# System_Clock_5 register map
Vendor: Texas Instruments
Peripheral module from a debugger description file (folder msp430).
Registers are 8-bit, read-write, reset 0x0 unless marked. A register's access mark holds for its fields unless they carry their own. Offsets are as the file gives them; lines under a group give offsets from that group; [hi:lo] are bit positions; {n}, {i} and the like mark numbered series; 'fields as' and 'values as' point back to an identical list; <NAME> marks a mode.

## System_Clock
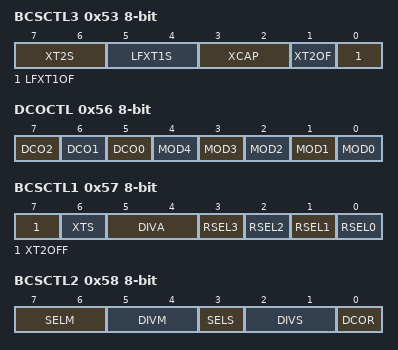
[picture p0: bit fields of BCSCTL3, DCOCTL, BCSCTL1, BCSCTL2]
0x53 BCSCTL3 — Basic Clock System Control 3
  [7:6] XT2S — Mode 0 for XT2
    0=Mode 0 for XT2 : 0.4 - 1 MHz; 1=Mode 1 for XT2 : 1 - 4 MHz; 2=Mode 2 for XT2 : 2 - 16 MHz; 3=Mode 3 for XT2 : Digital input signal
  [5:4] LFXT1S — Mode 0 for LFXT1 (XTS = 0)
    0=Mode 0 for LFXT1 : Normal operation; 1=Mode 1 for LFXT1 : Reserved; 2=Mode 2 for LFXT1 : VLO; 3=Mode 3 for LFXT1 : Digital input signal
  [3:2] XCAP — XIN/XOUT Cap 0
    0=XIN/XOUT Cap : 0 pF; 1=XIN/XOUT Cap : 6 pF; 2=XIN/XOUT Cap : 10 pF; 3=XIN/XOUT Cap : 12.5 pF
  [1] XT2OF — High frequency oscillator 2 fault flag
  [0] LFXT1OF — Low/high Frequency Oscillator Fault Flag
0x56 DCOCTL — DCO Clock Frequency Control
  [7] DCO2 — DCO Select Bit 2
  [6] DCO1 — DCO Select Bit 1
  [5] DCO0 — DCO Select Bit 0
  [n] MOD{n} (n=0..4) — Modulation Bit {n}
0x57 BCSCTL1 — Basic Clock System Control 1
  [7] XT2OFF — Enable XT2CLK
  [6] XTS — LFXTCLK 0:Low Freq. / 1: High Freq.
  [5:4] DIVA — ACLK Divider 0
    0=ACLK Divider 0: /1; 1=ACLK Divider 1: /2; 2=ACLK Divider 2: /4; 3=ACLK Divider 3: /8
  [n] RSEL{n} (n=0..3) — Range Select Bit {n}
0x58 BCSCTL2 — Basic Clock System Control 2
  [7:6] SELM — MCLK Source Select 0
    0=MCLK Source Select 0: DCOCLK; 1=MCLK Source Select 1: DCOCLK; 2=MCLK Source Select 2: XT2CLK/LFXTCLK; 3=MCLK Source Select 3: LFXTCLK
  [5:4] DIVM — MCLK Divider 0
    0=MCLK Divider 0: /1; 1=MCLK Divider 1: /2; 2=MCLK Divider 2: /4; 3=MCLK Divider 3: /8
  [3] SELS — SMCLK Source Select 0:DCOCLK / 1:XT2CLK/LFXTCLK
  [2:1] DIVS — SMCLK Divider 0
    0=SMCLK Divider 0: /1; 1=SMCLK Divider 1: /2; 2=SMCLK Divider 2: /4; 3=SMCLK Divider 3: /8
  [0] DCOR — Enable External Resistor : 1
